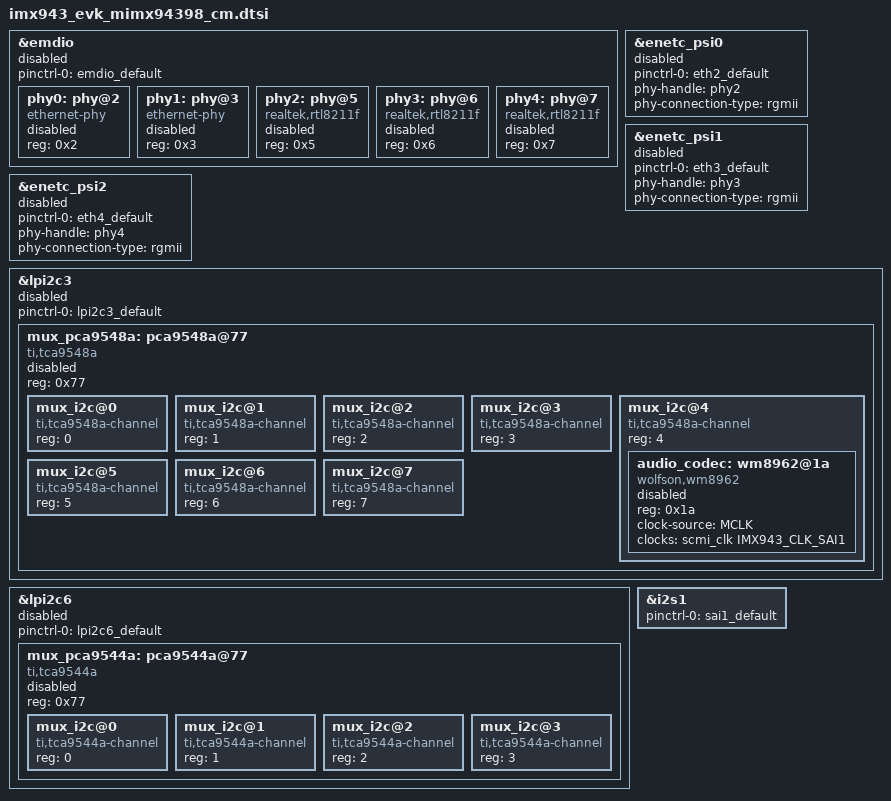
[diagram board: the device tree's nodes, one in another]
/*
 * Copyright 2025 NXP
 *
 * SPDX-License-Identifier: Apache-2.0
 */

&emdio {
	pinctrl-0 = <&emdio_default>;
	pinctrl-names = "default";
	status = "disabled";

	phy0: phy@2 {
		compatible = "ethernet-phy";
		reg = <0x2>;
		status = "disabled";
	};

	phy1: phy@3 {
		compatible = "ethernet-phy";
		reg = <0x3>;
		status = "disabled";
	};

	phy2: phy@5 {
		compatible = "realtek,rtl8211f";
		reg = <0x5>;
		status = "disabled";
	};

	phy3: phy@6 {
		compatible = "realtek,rtl8211f";
		reg = <0x6>;
		status = "disabled";
	};

	phy4: phy@7 {
		compatible = "realtek,rtl8211f";
		reg = <0x7>;
		status = "disabled";
	};
};

&enetc_psi0 {
	pinctrl-0 = <&eth2_default>;
	pinctrl-names = "default";
	phy-handle = <&phy2>;
	phy-connection-type = "rgmii";
	status = "disabled";
};

&enetc_psi1 {
	pinctrl-0 = <&eth3_default>;
	pinctrl-names = "default";
	phy-handle = <&phy3>;
	phy-connection-type = "rgmii";
	status = "disabled";
};

&enetc_psi2 {
	pinctrl-0 = <&eth4_default>;
	pinctrl-names = "default";
	phy-handle = <&phy4>;
	phy-connection-type = "rgmii";
	status = "disabled";
};

&lpi2c3 {
	pinctrl-0 = <&lpi2c3_default>;
	pinctrl-names = "default";
	status = "disabled";

	mux_pca9548a: pca9548a@77 {
		compatible = "ti,tca9548a";
		reg = <0x77>;
		#address-cells = <1>;
		#size-cells = <0>;
		status = "disabled";

		mux_i2c@0 {
			compatible = "ti,tca9548a-channel";
			reg = <0>;
			#address-cells = <1>;
			#size-cells = <0>;
		};

		mux_i2c@1 {
			compatible = "ti,tca9548a-channel";
			reg = <1>;
			#address-cells = <1>;
			#size-cells = <0>;
		};

		mux_i2c@2 {
			compatible = "ti,tca9548a-channel";
			reg = <2>;
			#address-cells = <1>;
			#size-cells = <0>;
		};

		mux_i2c@3 {
			compatible = "ti,tca9548a-channel";
			reg = <3>;
			#address-cells = <1>;
			#size-cells = <0>;
		};

		mux_i2c@4 {
			compatible = "ti,tca9548a-channel";
			reg = <4>;
			#address-cells = <1>;
			#size-cells = <0>;

			audio_codec: wm8962@1a {
				compatible = "wolfson,wm8962";
				reg = <0x1a>;
				clock-source = "MCLK";
				clocks = <&scmi_clk IMX943_CLK_SAI1>;
				clock-names = "mclk";
				status = "disabled";
			};
		};

		mux_i2c@5 {
			compatible = "ti,tca9548a-channel";
			reg = <5>;
			#address-cells = <1>;
			#size-cells = <0>;
		};

		mux_i2c@6 {
			compatible = "ti,tca9548a-channel";
			reg = <6>;
			#address-cells = <1>;
			#size-cells = <0>;
		};

		mux_i2c@7 {
			compatible = "ti,tca9548a-channel";
			reg = <7>;
			#address-cells = <1>;
			#size-cells = <0>;
		};
	};
};

&lpi2c6 {
	pinctrl-0 = <&lpi2c6_default>;
	pinctrl-names = "default";
	status = "disabled";

	mux_pca9544a: pca9544a@77 {
		compatible = "ti,tca9544a";
		reg = <0x77>;
		#address-cells = <1>;
		#size-cells = <0>;
		status = "disabled";

		mux_i2c@0 {
			compatible = "ti,tca9544a-channel";
			reg = <0>;
			#address-cells = <1>;
			#size-cells = <0>;
		};

		mux_i2c@1 {
			compatible = "ti,tca9544a-channel";
			reg = <1>;
			#address-cells = <1>;
			#size-cells = <0>;
		};

		mux_i2c@2 {
			compatible = "ti,tca9544a-channel";
			reg = <2>;
			#address-cells = <1>;
			#size-cells = <0>;
		};

		mux_i2c@3 {
			compatible = "ti,tca9544a-channel";
			reg = <3>;
			#address-cells = <1>;
			#size-cells = <0>;
		};
	};
};

&i2s1 {
	pinctrl-0 = <&sai1_default>;
	pinctrl-names = "default";
};
